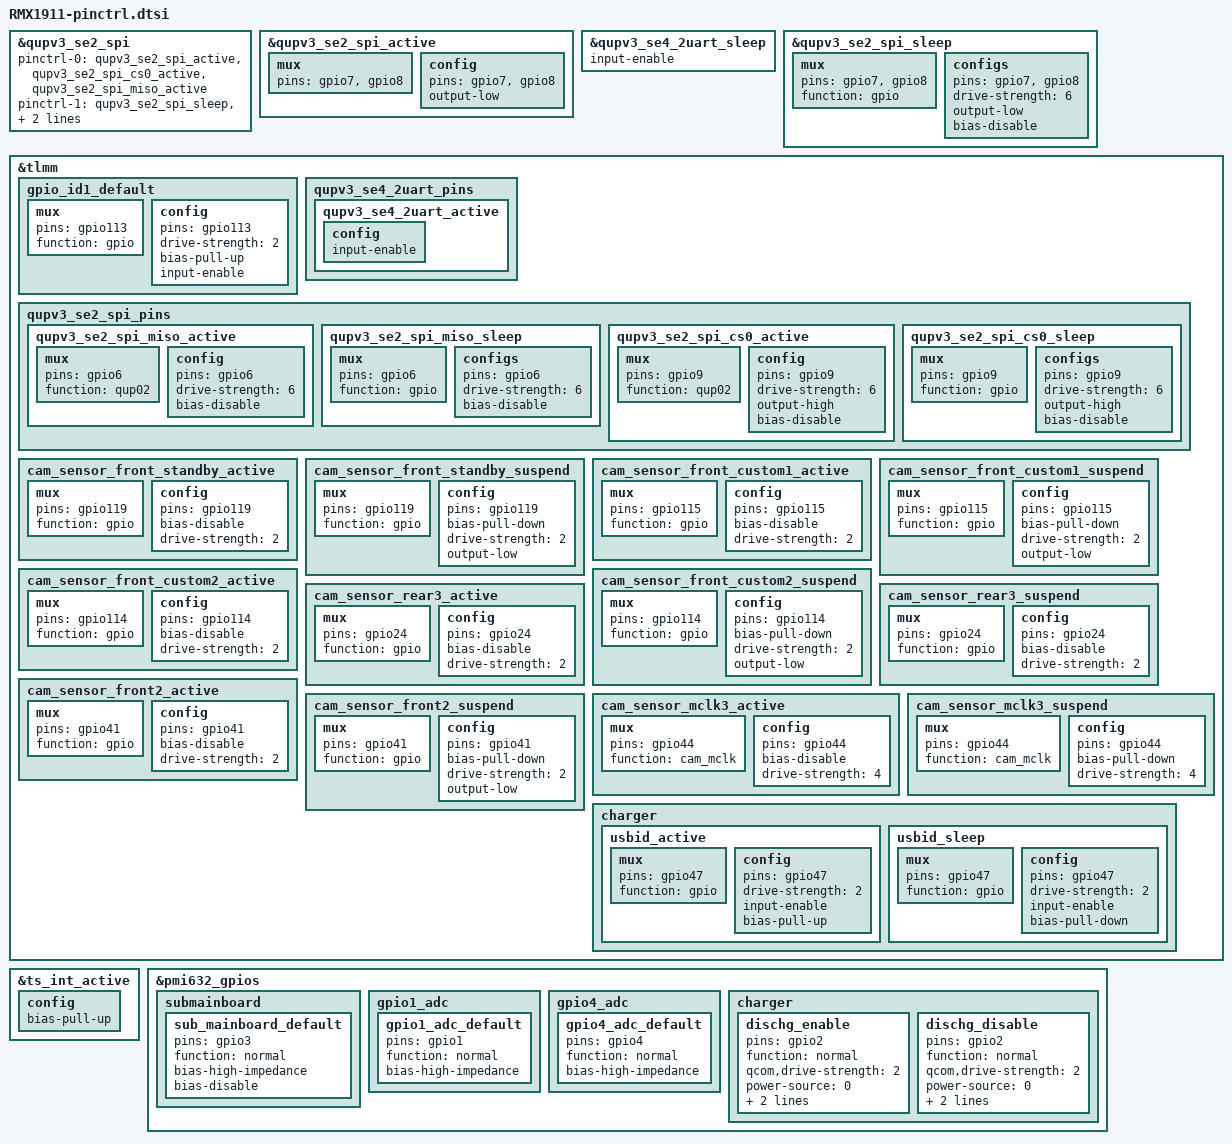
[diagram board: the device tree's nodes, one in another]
/* Copyright (c) 2018-2019, The Linux Foundation. All rights reserved.
 *
 * This program is free software; you can redistribute it and/or modify
 * it under the terms of the GNU General Public License version 2 and
 * only version 2 as published by the Free Software Foundation.
 *
 * This program is distributed in the hope that it will be useful,
 * but WITHOUT ANY WARRANTY; without even the implied warranty of
 * MERCHANTABILITY or FITNESS FOR A PARTICULAR PURPOSE.  See the
 * GNU General Public License for more details.
 */

&qupv3_se2_spi {
	pinctrl-0 = <&qupv3_se2_spi_active &qupv3_se2_spi_cs0_active &qupv3_se2_spi_miso_active>;
	pinctrl-1 = <&qupv3_se2_spi_sleep &qupv3_se2_spi_cs0_sleep &qupv3_se2_spi_miso_sleep>;
};

&qupv3_se2_spi_active {
	mux {
		pins = "gpio7", "gpio8";
	};

	config {
		pins = "gpio7", "gpio8";
		output-low;
	};
};

&qupv3_se4_2uart_sleep {
	input-enable;
};

&qupv3_se2_spi_sleep {
	mux {
		pins = "gpio7", "gpio8";
		function = "gpio";
	};

	configs {
		pins = "gpio7", "gpio8";
		drive-strength = <6>;
		output-low;
		bias-disable;
	};
};

&tlmm {
	gpio_id1_default: gpio_id1_default {
		mux {
			pins = "gpio113";
			function = "gpio";
		};

		config {
			pins = "gpio113";
			drive-strength = <2>;
			bias-pull-up;
			input-enable;
		};
	};

	qupv3_se4_2uart_pins: qupv3_se4_2uart_pins {
		qupv3_se4_2uart_active: qupv3_se4_2uart_active {
			config {
				input-enable;
			};
		};
	};

	qupv3_se2_spi_pins: qupv3_se2_spi_pins {
		qupv3_se2_spi_miso_active: qupv3_se2_spi_miso_active {
			mux {
				pins = "gpio6";
				function = "qup02";
			};

			config {
				pins = "gpio6";
				drive-strength = <6>;
				bias-disable;
			};
		};

		qupv3_se2_spi_miso_sleep: qupv3_se2_spi_miso_sleep {
			mux {
				pins = "gpio6";
				function = "gpio";
			};

			configs {
				pins = "gpio6";
				drive-strength = <6>;
				bias-disable;
			};
		};
		qupv3_se2_spi_cs0_active: qupv3_se2_spi_cs0_active {
			mux {
				pins = "gpio9";
				function = "qup02";
			};

			config {
				pins = "gpio9";
				drive-strength = <6>;
				output-high;
				bias-disable;
			};
		};

		qupv3_se2_spi_cs0_sleep: qupv3_se2_spi_cs0_sleep {
			mux {
				pins = "gpio9";
				function = "gpio";
			};

			configs {
				pins = "gpio9";
				drive-strength = <6>;
				output-high;
				bias-disable;
			};
		};
	};

	cam_sensor_front_standby_active: cam_sensor_front_standby_active {
		/* RESET  */
		mux {
			pins = "gpio119";
			function = "gpio";
		};

		config {
			pins = "gpio119";
			bias-disable; /* No PULL */
			drive-strength = <2>; /* 2 MA */
		};
	};

	cam_sensor_front_standby_suspend: cam_sensor_front_standby_suspend {
		/* RESET */
		mux {
			pins = "gpio119";
			function = "gpio";
		};

		config {
			pins = "gpio119";
			bias-pull-down; /* PULL DOWN */
			drive-strength = <2>; /* 2 MA */
			output-low;
		};
	};

	cam_sensor_front_custom1_active: cam_sensor_front_custom1_active {
		/* RESET  */
		mux {
			pins = "gpio115";
			function = "gpio";
		};

		config {
			pins = "gpio115";
			bias-disable; /* No PULL */
			drive-strength = <2>; /* 2 MA */
		};
	};

	cam_sensor_front_custom1_suspend: cam_sensor_front_custom1_suspend {
		/* RESET */
		mux {
			pins =  "gpio115";
			function = "gpio";
		};

		config {
			pins = "gpio115";
			bias-pull-down; /* PULL DOWN */
			drive-strength = <2>; /* 2 MA */
			output-low;
		};
	};

	cam_sensor_front_custom2_active: cam_sensor_front_custom2_active {
		/* RESET  */
		mux {
			pins = "gpio114";
			function = "gpio";
		};

		config {
			pins = "gpio114";
			bias-disable; /* No PULL */
			drive-strength = <2>; /* 2 MA */
		};
	};

	cam_sensor_front_custom2_suspend: cam_sensor_front_custom2_suspend {
		/* RESET */
		mux {
			pins =  "gpio114";
			function = "gpio";
		};

		config {
			pins = "gpio114";
			bias-pull-down; /* PULL DOWN */
			drive-strength = <2>; /* 2 MA */
			output-low;
		};
	};

	cam_sensor_rear3_active: cam_sensor_rear3_active {
		/* RESET */
		mux {
			pins = "gpio24";
			function = "gpio";
		};

		config {
			pins = "gpio24";
			bias-disable; /* No PULL */
			drive-strength = <2>; /* 2 MA */
		};
	};

	cam_sensor_rear3_suspend: cam_sensor_rear3_suspend {
		/* RESET */
		mux {
			pins = "gpio24";
			function = "gpio";
		};

		config {
			pins = "gpio24";
			bias-disable; /* No PULL */
			drive-strength = <2>; /* 2 MA */
		};
	};

	cam_sensor_front2_active: cam_sensor_front2_active {
		/*PWDN RESET*/
		mux {
			pins = "gpio41";
			function = "gpio";
		};

		config {
			pins = "gpio41";
			bias-disable; /* No PULL */
			drive-strength = <2>; /* 2 MA */
		};
	};

	cam_sensor_front2_suspend: cam_sensor_front2_suspend {
		/*PWDN RESET*/
		mux {
			pins = "gpio41";
			function = "gpio";
		};

		config {
			pins = "gpio41";
			bias-pull-down; /* PULL DOWN */
			drive-strength = <2>; /* 2 MA */
			output-low;
		};
	};

	cam_sensor_mclk3_active: cam_sensor_mclk3_active {
		/* MCLK3 */
		mux {
			pins = "gpio44";
			function = "cam_mclk";
		};

		config {
			pins = "gpio44";
			bias-disable; /* No PULL */
			drive-strength = <4>; /* 4 MA */
		};
	};

	cam_sensor_mclk3_suspend: cam_sensor_mclk3_suspend {
		/* MCLK2 */
		mux {
			pins = "gpio44";
			function = "cam_mclk";
		};

		config {
			pins = "gpio44";
			bias-pull-down; /* PULL DOWN */
			drive-strength = <4>; /* 4 MA */
		};
	};

	charger: charger {
		usbid_active: usbid_active {
			mux {
				pins = "gpio47";
				function = "gpio";
			};

			config {
				pins = "gpio47";
				drive-strength = <2>;
				input-enable;
				bias-pull-up;
			};
		};

		usbid_sleep: usbid_sleep {
			mux {
				pins = "gpio47";
				function = "gpio";
			};

			config {
				pins = "gpio47";
				drive-strength = <2>;
				input-enable;
				bias-pull-down;
			};
		};
	};
};

&ts_int_active {
	config {
		/delete-property/ bias-pull-down;
		bias-pull-up;
	};
};

&pmi632_gpios {
	submainboard {
		sub_mainboard_default: sub_mainboard_default{
			pins = "gpio3";
			function = "normal"; /* normal */
			bias-high-impedance; /* disable GPIO for ADC*/
			bias-disable;
		};
	};
	gpio1_adc {
		gpio1_adc_default: gpio1_adc_default {
			pins = "gpio1"; /* GPIO 1 */
			function = "normal"; /* normal */
			bias-high-impedance; /* DISABLE GPIO1 for ADC*/
		};
	};

	gpio4_adc {
		gpio4_adc_default: gpio4_adc_default {
			pins = "gpio4"; /* GPIO 4 */
			function = "normal"; /* normal */
			bias-high-impedance; /* DISABLE GPIO4 for ADC*/
			};
	};

	charger {
		dischg_enable: dischg_enable{
			pins = "gpio2";
			function = "normal";
			qcom,drive-strength = <2>;
			power-source = <0>;
			bias-disable;
			output-high;
		};

		dischg_disable: dischg_disable{
			pins = "gpio2";
			function = "normal";
			qcom,drive-strength = <2>;
			power-source = <0>;
			bias-disable;
			output-low;
		};
	};
};
